# R5FSS0_COMPARE_CFG register map
Vendor: Texas Instruments
Peripheral module from a debugger description file (folder J7VCL).
Registers are 32-bit, access per field, reset 0x0 unless marked. A register's access mark holds for its fields unless they carry their own. Offsets are as the file gives them; lines under a group give offsets from that group; [hi:lo] are bit positions; {n}, {i} and the like mark numbered series; 'fields as' and 'values as' point back to an identical list; <NAME> marks a mode.

## R5FSS0_COMPARE_CFG
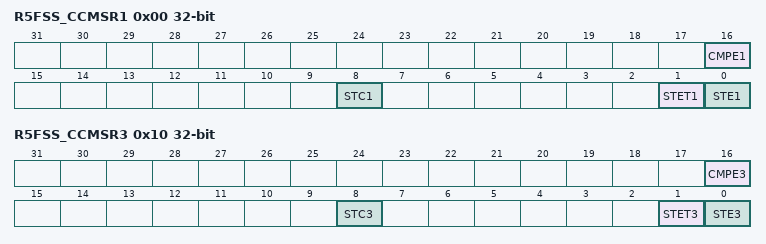
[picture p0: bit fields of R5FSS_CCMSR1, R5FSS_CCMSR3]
0x00 R5FSS_CCMSR1 — This register shows the error and self-test status of the CPU output compare block.
  [16] CMPE1 rw — Compare error for CPU output compare diagnostic.
  [8] STC1 rw — Self-test complete for CPU output compare diagnostic.
  [1] STET1 rw — Self-test error type for CPU output compare diagnostic.
  [0] STE1 rw — Self-test error for CPU output compare diagnostic.
0x04 R5FSS_CCMKEYR1 — This register is used to select the operating mode of the CPU output compare block.
  [3:0] MKEY1 rw — Mode key to select operation for CPU output compare diagnostic.
0x10 R5FSS_CCMSR3 — This register shows the error and self-test status of the inactivity monitor block.
  [16] CMPE3 rw — Compare error for inactivity monitor.
  [8] STC3 rw — Self-test complete for inactivity monitor.
  [1] STET3 rw — Self-test error type for inactivity monitor.
  [0] STE3 rw — Self-test error for inactivity monitor.
0x14 R5FSS_CCMKEYR3 — This register is used to select the operating mode of the inactivity monitor block.
  [3:0] MKEY3 rw — Mode key to select operation for CPU output compare diagnostic.
0x18 R5FSS_CCMPOLCNTRL — This register is used for polarity inversion of CPU compare signals.
  [7:0] POL_INV rw — Polarity inversion. This value is used to invert one of the 8 output compare signals from CPU1 to the R5FSS_CCMR5. Inverting any one signal will lead to compare error by the CPU output compare diagnostic.
